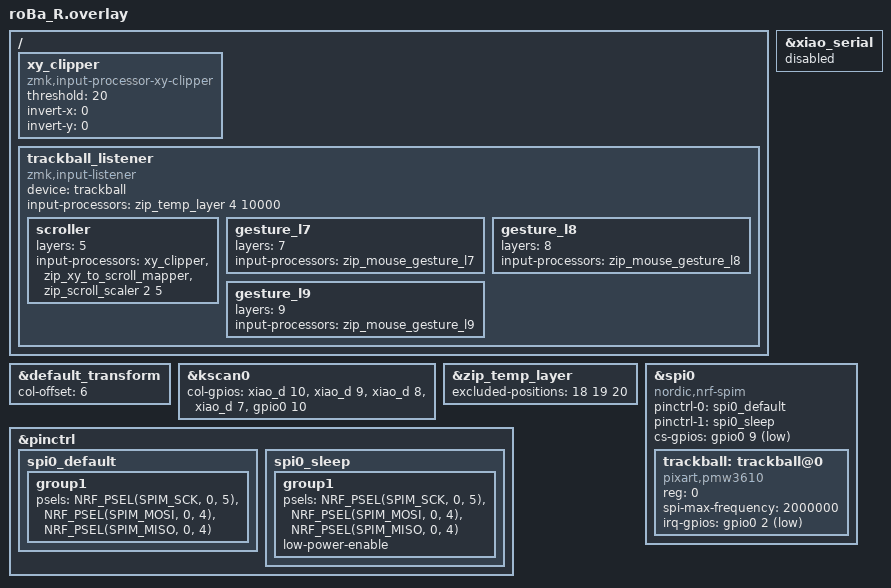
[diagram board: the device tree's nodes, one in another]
#include "roBa.dtsi"
#include <dt-bindings/zmk/input_transform.h>
#include <dt-bindings/input/input-event-codes.h>
#include <input/processors.dtsi>

/* mouse gesture */
#include <mouse-gesture.dtsi>
#include "../../../config/gesture/gesture_L7.dtsi"
#include "../../../config/gesture/gesture_L8.dtsi"
#include "../../../config/gesture/gesture_L9.dtsi"

&default_transform {
    col-offset = <6>;
};

&kscan0 {
    col-gpios
        = <&xiao_d 10 GPIO_ACTIVE_HIGH>
        , <&xiao_d 9 GPIO_ACTIVE_HIGH>
        , <&xiao_d 8 GPIO_ACTIVE_HIGH>
        , <&xiao_d 7 GPIO_ACTIVE_HIGH>
        , <&gpio0 10 GPIO_ACTIVE_HIGH>
        ;
};

/ {
    /* diagonal clipper for scroll */
    xy_clipper: xy_clipper {
        compatible = "zmk,input-processor-xy-clipper";
        #input-processor-cells = <0>;
        threshold = <20>;
        invert-x = <0>;
        invert-y = <0>;
    };

    trackball_listener {
        status = "okay";
        compatible = "zmk,input-listener";
        device = <&trackball>;

        /* AML: move trackball -> temp layer 4 (MOUSE) for 10s */
        input-processors = <&zip_temp_layer 4 10000>;

        /* Scroll layer (L5) */
        scroller {
            layers = <5>;
            input-processors =
                <&xy_clipper>,
                <&zip_xy_to_scroll_mapper>,
                <&zip_scroll_scaler 2 5>;
        };

        /* Gesture layers (L7/L8/L9) */
        gesture_l7 { layers = <7>; input-processors = <&zip_mouse_gesture_l7>; };
        gesture_l8 { layers = <8>; input-processors = <&zip_mouse_gesture_l8>; };
        gesture_l9 { layers = <9>; input-processors = <&zip_mouse_gesture_l9>; };
    };
};

/* AML: do NOT exit when pressing J/K/L */
&zip_temp_layer {
    excluded-positions = <
        18 /* J */
        19 /* K */
        20 /* L */
    >;
};

&pinctrl {
    spi0_default: spi0_default {
        group1 {
            psels = <NRF_PSEL(SPIM_SCK, 0, 5)>,
                <NRF_PSEL(SPIM_MOSI, 0, 4)>,
                <NRF_PSEL(SPIM_MISO, 0, 4)>;
        };
    };

    spi0_sleep: spi0_sleep {
        group1 {
            psels = <NRF_PSEL(SPIM_SCK, 0, 5)>,
                <NRF_PSEL(SPIM_MOSI, 0, 4)>,
                <NRF_PSEL(SPIM_MISO, 0, 4)>;
            low-power-enable;
        };
    };
};

&xiao_serial { status = "disabled"; };

&spi0 {
    status = "okay";
    compatible = "nordic,nrf-spim";
    pinctrl-0 = <&spi0_default>;
    pinctrl-1 = <&spi0_sleep>;
    pinctrl-names = "default", "sleep";
    cs-gpios = <&gpio0 9 GPIO_ACTIVE_LOW>;

    trackball: trackball@0 {
        status = "okay";
        compatible = "pixart,pmw3610";
        reg = <0>;
        spi-max-frequency = <2000000>;
        irq-gpios = <&gpio0 2 (GPIO_ACTIVE_LOW | GPIO_PULL_UP)>;
    };
};
